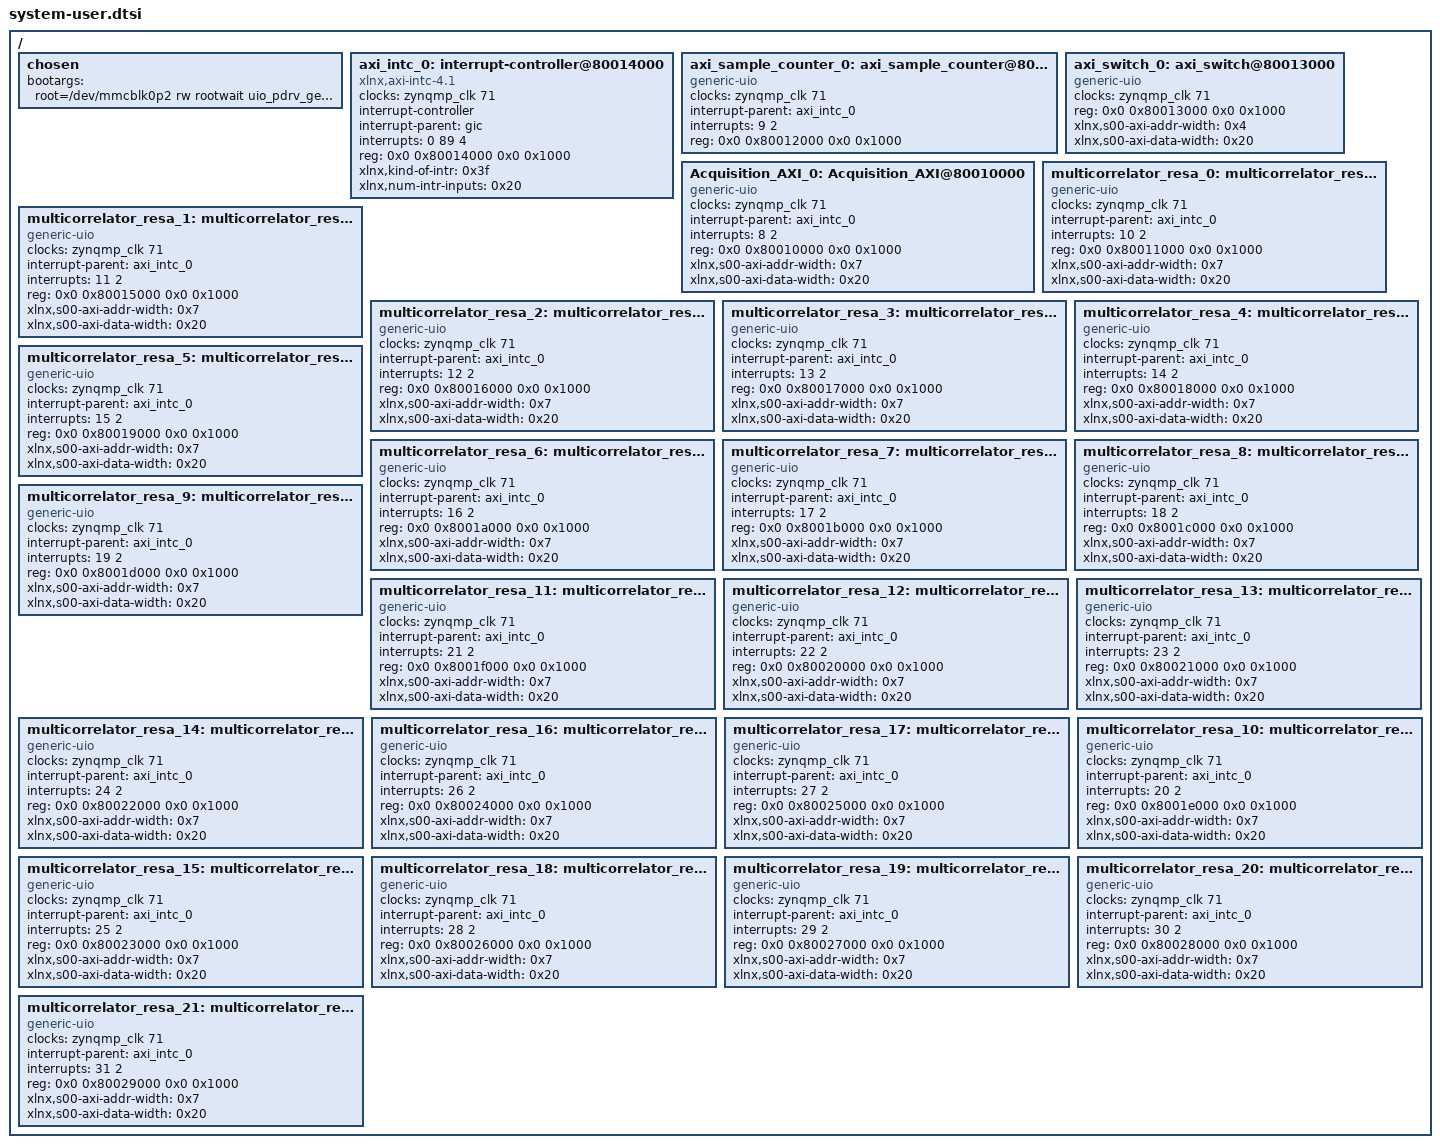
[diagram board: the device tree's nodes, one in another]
/include/ "system-conf.dtsi"
/ {
};
/ {

chosen {
	bootargs = "root=/dev/mmcblk0p2 rw rootwait uio_pdrv_genirq.of_id=generic-uio rootfstype=ext4 earlyprintk clk_ignore_unused cma=1024M cpuidle.off=1";
	};

	                axi_intc_0: interrupt-controller@80014000 {
                        #interrupt-cells = <2>;
                        clock-names = "s_axi_aclk";
                        clocks = <&zynqmp_clk 71>;
                        compatible = "xlnx,axi-intc-4.1", "xlnx,xps-intc-1.00.a";
                        interrupt-controller;
			interrupt-parent = <&gic>;
                        interrupts = <0 89 4>;
                        reg = <0x0 0x80014000 0x0 0x1000>;
                        xlnx,kind-of-intr = <0x3f>;
                        xlnx,num-intr-inputs = <0x20>;
                };
                axi_sample_counter_0: axi_sample_counter@80012000 {
                        clock-names = "s_axi_aclk";
                        clocks = <&zynqmp_clk 71>;
                        compatible = "generic-uio";
                        interrupt-names = "o_irq";
                        interrupt-parent = <&axi_intc_0>;
                        interrupts = <9 2>;
                        reg = <0x0 0x80012000 0x0 0x1000>;
                };
                axi_switch_0: axi_switch@80013000 {
                        clock-names = "s00_axi_aclk";
                        clocks = <&zynqmp_clk 71>;
                        compatible = "generic-uio";
                        reg = <0x0 0x80013000 0x0 0x1000>;
                        xlnx,s00-axi-addr-width = <0x4>;
                        xlnx,s00-axi-data-width = <0x20>;
                };

	   Acquisition_AXI_0: Acquisition_AXI@80010000 {
                        clock-names = "s00_axi_aclk";
                        clocks = <&zynqmp_clk 71>;
                        compatible = "generic-uio";
                        interrupt-names = "irq";
                        interrupt-parent = <&axi_intc_0>;
                        interrupts = <8 2>;
                        reg = <0x0 0x80010000 0x0 0x1000>;
                        xlnx,s00-axi-addr-width = <0x7>;
                        xlnx,s00-axi-data-width = <0x20>;
                };
	   multicorrelator_resa_0: multicorrelator_resampler_S00_AXI@80011000 {
                        clock-names = "s00_axi_aclk";
                        clocks = <&zynqmp_clk 71>;
                        compatible = "generic-uio";
                        interrupt-names = "irq";
                        interrupt-parent = <&axi_intc_0>;
                        interrupts = <10 2>;
                        reg = <0x0 0x80011000 0x0 0x1000>;
                        xlnx,s00-axi-addr-width = <0x7>;
                        xlnx,s00-axi-data-width = <0x20>;
                };
               multicorrelator_resa_1: multicorrelator_resampler_S00_AXI@80015000 {
                        clock-names = "s00_axi_aclk";
                        clocks = <&zynqmp_clk 71>;
                        compatible = "generic-uio";
                        interrupt-names = "irq";
                        interrupt-parent = <&axi_intc_0>;
                        interrupts = <11 2>;
                        reg = <0x0 0x80015000 0x0 0x1000>;
                        xlnx,s00-axi-addr-width = <0x7>;
                        xlnx,s00-axi-data-width = <0x20>;
                };
                multicorrelator_resa_2: multicorrelator_resampler_S00_AXI@80016000 {
                        clock-names = "s00_axi_aclk";
                        clocks = <&zynqmp_clk 71>;
                        compatible = "generic-uio";
                        interrupt-names = "irq";
                        interrupt-parent = <&axi_intc_0>;
                        interrupts = <12 2>;
                        reg = <0x0 0x80016000 0x0 0x1000>;
                        xlnx,s00-axi-addr-width = <0x7>;
                        xlnx,s00-axi-data-width = <0x20>;
                };
                multicorrelator_resa_3: multicorrelator_resampler_S00_AXI@80017000 {
                        clock-names = "s00_axi_aclk";
                        clocks = <&zynqmp_clk 71>;
                        compatible = "generic-uio";
                        interrupt-names = "irq";
                        interrupt-parent = <&axi_intc_0>;
                        interrupts = <13 2>;
                        reg = <0x0 0x80017000 0x0 0x1000>;
                        xlnx,s00-axi-addr-width = <0x7>;
                        xlnx,s00-axi-data-width = <0x20>;
                };
                multicorrelator_resa_4: multicorrelator_resampler_S00_AXI@80018000 {
                        clock-names = "s00_axi_aclk";
                        clocks = <&zynqmp_clk 71>;
                        compatible = "generic-uio";
                        interrupt-names = "irq";
                        interrupt-parent = <&axi_intc_0>;
                        interrupts = <14 2>;
                        reg = <0x0 0x80018000 0x0 0x1000>;
                        xlnx,s00-axi-addr-width = <0x7>;
                        xlnx,s00-axi-data-width = <0x20>;
                };
	      multicorrelator_resa_5: multicorrelator_resampler_S00_AXI@80019000 {
                        clock-names = "s00_axi_aclk";
                        clocks = <&zynqmp_clk 71>;
                        compatible = "generic-uio";
                        interrupt-names = "irq";
                        interrupt-parent = <&axi_intc_0>;
                        interrupts = <15 2>;
                        reg = <0x0 0x80019000 0x0 0x1000>;
                        xlnx,s00-axi-addr-width = <0x7>;
                        xlnx,s00-axi-data-width = <0x20>;
                };
                multicorrelator_resa_6: multicorrelator_resampler_S00_AXI@8001a000 {
                        clock-names = "s00_axi_aclk";
                        clocks = <&zynqmp_clk 71>;
                        compatible = "generic-uio";
                        interrupt-names = "irq";
                        interrupt-parent = <&axi_intc_0>;
                        interrupts = <16 2>;
                        reg = <0x0 0x8001a000 0x0 0x1000>;
                        xlnx,s00-axi-addr-width = <0x7>;
                        xlnx,s00-axi-data-width = <0x20>;
                };
                multicorrelator_resa_7: multicorrelator_resampler_S00_AXI@8001b000 {
                        clock-names = "s00_axi_aclk";
                        clocks = <&zynqmp_clk 71>;
                        compatible = "generic-uio";
                        interrupt-names = "irq";
                        interrupt-parent = <&axi_intc_0>;
                        interrupts = <17 2>;
                        reg = <0x0 0x8001b000 0x0 0x1000>;
                        xlnx,s00-axi-addr-width = <0x7>;
                        xlnx,s00-axi-data-width = <0x20>;
                };
                multicorrelator_resa_8: multicorrelator_resampler_S00_AXI@8001c000 {
                        clock-names = "s00_axi_aclk";
                        clocks = <&zynqmp_clk 71>;
                        compatible = "generic-uio";
                        interrupt-names = "irq";
                        interrupt-parent = <&axi_intc_0>;
                        interrupts = <18 2>;
                        reg = <0x0 0x8001c000 0x0 0x1000>;
                        xlnx,s00-axi-addr-width = <0x7>;
                        xlnx,s00-axi-data-width = <0x20>;
                };
	multicorrelator_resa_9: multicorrelator_resampler_S00_AXI@8001d000 {
                        clock-names = "s00_axi_aclk";
                        clocks = <&zynqmp_clk 71>;
                        compatible = "generic-uio";
                        interrupt-names = "irq";
                        interrupt-parent = <&axi_intc_0>;
                        interrupts = <19 2>;
                        reg = <0x0 0x8001d000 0x0 0x1000>;
                        xlnx,s00-axi-addr-width = <0x7>;
                        xlnx,s00-axi-data-width = <0x20>;
                };
                multicorrelator_resa_11: multicorrelator_resampler_5_1_AXI@8001f000 {
                        clock-names = "s00_axi_aclk";
                        clocks = <&zynqmp_clk 71>;
                        compatible = "generic-uio";
                        interrupt-names = "irq";
                        interrupt-parent = <&axi_intc_0>;
                        interrupts = <21 2>;
                        reg = <0x0 0x8001f000 0x0 0x1000>;
                        xlnx,s00-axi-addr-width = <0x7>;
                        xlnx,s00-axi-data-width = <0x20>;
                };
		       multicorrelator_resa_12: multicorrelator_resampler_5_1_AXI@80020000 {
                        clock-names = "s00_axi_aclk";
                        clocks = <&zynqmp_clk 71>;
                        compatible = "generic-uio";
                        interrupt-names = "irq";
                        interrupt-parent = <&axi_intc_0>;
                        interrupts = <22 2>;
                        reg = <0x0 0x80020000 0x0 0x1000>;
                        xlnx,s00-axi-addr-width = <0x7>;
                        xlnx,s00-axi-data-width = <0x20>;
                };
                multicorrelator_resa_13: multicorrelator_resampler_5_1_AXI@80021000 {
                        clock-names = "s00_axi_aclk";
                        clocks = <&zynqmp_clk 71>;
                        compatible = "generic-uio";
                        interrupt-names = "irq";
                        interrupt-parent = <&axi_intc_0>;
                        interrupts = <23 2>;
                        reg = <0x0 0x80021000 0x0 0x1000>;
                        xlnx,s00-axi-addr-width = <0x7>;
                        xlnx,s00-axi-data-width = <0x20>;
                };
                multicorrelator_resa_14: multicorrelator_resampler_5_1_AXI@80022000 {
                        clock-names = "s00_axi_aclk";
                        clocks = <&zynqmp_clk 71>;
                        compatible = "generic-uio";
                        interrupt-names = "irq";
                        interrupt-parent = <&axi_intc_0>;
                        interrupts = <24 2>;
                        reg = <0x0 0x80022000 0x0 0x1000>;
                        xlnx,s00-axi-addr-width = <0x7>;
                        xlnx,s00-axi-data-width = <0x20>;
                };
                multicorrelator_resa_16: multicorrelator_resampler_5_1_AXI@80024000 {
                        clock-names = "s00_axi_aclk";
                        clocks = <&zynqmp_clk 71>;
                        compatible = "generic-uio";
                        interrupt-names = "irq";
                        interrupt-parent = <&axi_intc_0>;
                        interrupts = <26 2>;
                        reg = <0x0 0x80024000 0x0 0x1000>;
                        xlnx,s00-axi-addr-width = <0x7>;
                        xlnx,s00-axi-data-width = <0x20>;
                };
                multicorrelator_resa_17: multicorrelator_resampler_5_1_AXI@80025000 {
                        clock-names = "s00_axi_aclk";
                        clocks = <&zynqmp_clk 71>;
                        compatible = "generic-uio";
                        interrupt-names = "irq";
                        interrupt-parent = <&axi_intc_0>;
                        interrupts = <27 2>;
                        reg = <0x0 0x80025000 0x0 0x1000>;
                        xlnx,s00-axi-addr-width = <0x7>;
                        xlnx,s00-axi-data-width = <0x20>;
                };

	                multicorrelator_resa_10: multicorrelator_resampler_3_1@8001e000 {
                        clock-names = "s00_axi_aclk";
                        clocks = <&zynqmp_clk 71>;
                        compatible = "generic-uio";
                        interrupt-names = "irq";
                        interrupt-parent = <&axi_intc_0>;
                        interrupts = <20 2>;
                        reg = <0x0 0x8001e000 0x0 0x1000>;
                        xlnx,s00-axi-addr-width = <0x7>;
                        xlnx,s00-axi-data-width = <0x20>;
                };
		                multicorrelator_resa_15: multicorrelator_resampler_3_1@80023000 {
                        clock-names = "s00_axi_aclk";
                        clocks = <&zynqmp_clk 71>;
                        compatible = "generic-uio";
                        interrupt-names = "irq";
                        interrupt-parent = <&axi_intc_0>;
                        interrupts = <25 2>;
                        reg = <0x0 0x80023000 0x0 0x1000>;
                        xlnx,s00-axi-addr-width = <0x7>;
                        xlnx,s00-axi-data-width = <0x20>;
                };
		multicorrelator_resa_18: multicorrelator_resampler_3_1@80026000 {
                        clock-names = "s00_axi_aclk";
                        clocks = <&zynqmp_clk 71>;
                        compatible = "generic-uio";
                        interrupt-names = "irq";
                        interrupt-parent = <&axi_intc_0>;
                        interrupts = <28 2>;
                        reg = <0x0 0x80026000 0x0 0x1000>;
                        xlnx,s00-axi-addr-width = <0x7>;
                        xlnx,s00-axi-data-width = <0x20>;
                };
                multicorrelator_resa_19: multicorrelator_resampler_3_1@80027000 {
                        clock-names = "s00_axi_aclk";
                        clocks = <&zynqmp_clk 71>;
                        compatible = "generic-uio";
                        interrupt-names = "irq";
                        interrupt-parent = <&axi_intc_0>;
                        interrupts = <29 2>;
                        reg = <0x0 0x80027000 0x0 0x1000>;
                        xlnx,s00-axi-addr-width = <0x7>;
                        xlnx,s00-axi-data-width = <0x20>;
                };
   		 multicorrelator_resa_20: multicorrelator_resampler_3_1@80028000 {
                        clock-names = "s00_axi_aclk";
                        clocks = <&zynqmp_clk 71>;
                        compatible = "generic-uio";
                        interrupt-names = "irq";
                        interrupt-parent = <&axi_intc_0>;
                        interrupts = <30 2>;
                        reg = <0x0 0x80028000 0x0 0x1000>;
                        xlnx,s00-axi-addr-width = <0x7>;
                        xlnx,s00-axi-data-width = <0x20>;
                };
	 	multicorrelator_resa_21: multicorrelator_resampler_3_1@80029000 {
                        clock-names = "s00_axi_aclk";
                        clocks = <&zynqmp_clk 71>;
                        compatible = "generic-uio";
                        interrupt-names = "irq";
                        interrupt-parent = <&axi_intc_0>;
                        interrupts = <31 2>;
                        reg = <0x0 0x80029000 0x0 0x1000>;
                        xlnx,s00-axi-addr-width = <0x7>;
                        xlnx,s00-axi-data-width = <0x20>;
                };







};
